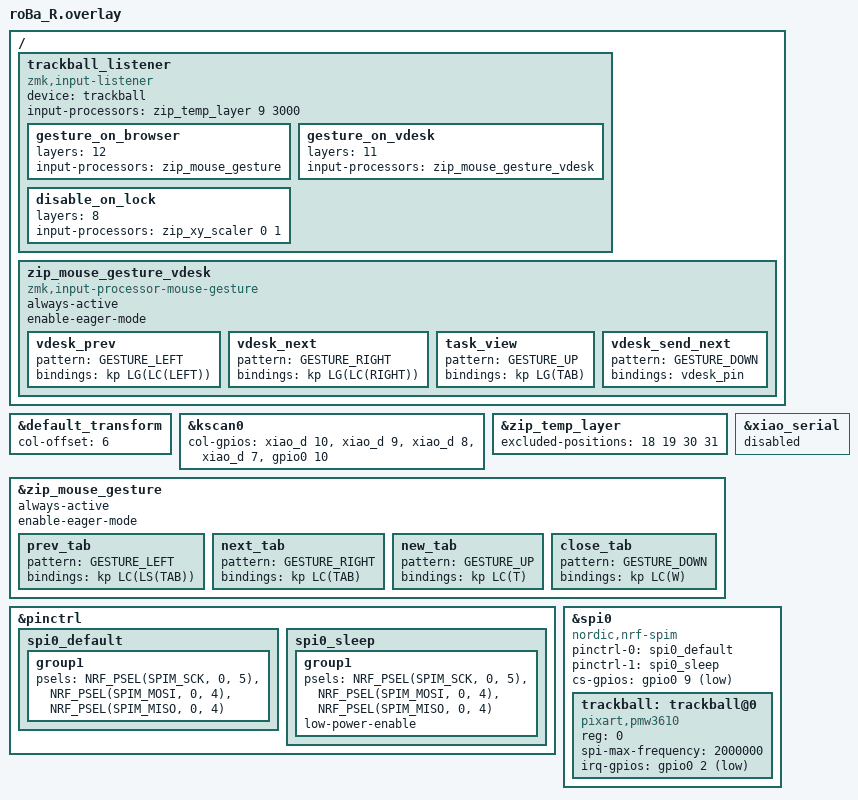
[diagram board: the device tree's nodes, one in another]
#include "roBa.dtsi"
#include <behaviors.dtsi>
#include <dt-bindings/zmk/keys.h>
#include <input/processors.dtsi>
#include <mouse-gesture.dtsi>

&default_transform {
    col-offset = <6>;
};

&kscan0 {
        col-gpios
            = <&xiao_d 10 GPIO_ACTIVE_HIGH>
            , <&xiao_d 9 GPIO_ACTIVE_HIGH>
            , <&xiao_d 8 GPIO_ACTIVE_HIGH>
            , <&xiao_d 7 GPIO_ACTIVE_HIGH>
            , <&gpio0 10 GPIO_ACTIVE_HIGH>
            ;
};

/ {
    trackball_listener {
        status = "okay";
        compatible = "zmk,input-listener";
        device = <&trackball>;
        // トラックボールが動いたらレイヤー9(MOUSE)を有効化し、3000ms動きが無ければ自動解除
        input-processors = <&zip_temp_layer 9 3000>;

        // MOUSE-BROWSER(レイヤー12)の間はトラックボールの動きを常にジェスチャーとして扱う
        gesture_on_browser {
            layers = <12>;
            input-processors = <&zip_mouse_gesture>;
        };

        // MOUSE-VERTIALDESKTOP(レイヤー11)の間はトラックボールの動きを常にジェスチャーとして扱う
        gesture_on_vdesk {
            layers = <11>;
            input-processors = <&zip_mouse_gesture_vdesk>;
        };

        // LOCK(レイヤー8、チャイルドロック中)はX/Y移動量を0倍にしてトラックボールを無効化
        disable_on_lock {
            layers = <8>;
            input-processors = <&zip_xy_scaler 0 1>;
        };
    };

    // MOUSE-BROWSERとは別パターンにするため、別インスタンスとして定義
    zip_mouse_gesture_vdesk: zip_mouse_gesture_vdesk {
        compatible = "zmk,input-processor-mouse-gesture";
        #input-processor-cells = <0>;
        always-active;
        enable-eager-mode;

        vdesk_prev {
            pattern = <GESTURE_LEFT>;
            bindings = <&kp LG(LC(LEFT))>;
        };

        vdesk_next {
            pattern = <GESTURE_RIGHT>;
            bindings = <&kp LG(LC(RIGHT))>;
        };

        task_view {
            pattern = <GESTURE_UP>;
            bindings = <&kp LG(TAB)>;
        };

        vdesk_send_next {
            pattern = <GESTURE_DOWN>;
            // Win+Tab -> Shift+F10 -> 下矢印x3 -> Enter で
            // タスクビューの右クリックメニューから「このウィンドウをすべてのデスクトップに表示する」を選ぶ
            bindings = <&vdesk_pin>;
        };
    };
};

&zip_temp_layer {
    // MOUSEレイヤーに割り当て済みのキー(J/K/M/mo10位置)は押してもレイヤーを解除しない
    excluded-positions = <18 19 30 31>;
};

&zip_mouse_gesture {
    always-active;
    enable-eager-mode;

    prev_tab {
        pattern = <GESTURE_LEFT>;
        bindings = <&kp LC(LS(TAB))>;
    };

    next_tab {
        pattern = <GESTURE_RIGHT>;
        bindings = <&kp LC(TAB)>;
    };

    new_tab {
        pattern = <GESTURE_UP>;
        bindings = <&kp LC(T)>;
    };

    close_tab {
        pattern = <GESTURE_DOWN>;
        bindings = <&kp LC(W)>;
    };
};

&pinctrl {
    spi0_default: spi0_default {
        group1 {
            psels = <NRF_PSEL(SPIM_SCK, 0, 5)>,
                <NRF_PSEL(SPIM_MOSI, 0, 4)>,
                <NRF_PSEL(SPIM_MISO, 0, 4)>;
        };
    };

    spi0_sleep: spi0_sleep {
        group1 {
            psels = <NRF_PSEL(SPIM_SCK, 0, 5)>,
                <NRF_PSEL(SPIM_MOSI, 0, 4)>,
                <NRF_PSEL(SPIM_MISO, 0, 4)>;
            low-power-enable;
        };
    };
};

&xiao_serial { status = "disabled"; };

&spi0 {
    status = "okay";
    compatible = "nordic,nrf-spim";
    pinctrl-0 = <&spi0_default>;
    pinctrl-1 = <&spi0_sleep>;
    pinctrl-names = "default", "sleep";
    cs-gpios = <&gpio0 9 GPIO_ACTIVE_LOW>;

    trackball: trackball@0 {
        status = "okay";
        compatible = "pixart,pmw3610";
        reg = <0>;
        spi-max-frequency = <2000000>;
        irq-gpios = <&gpio0 2 (GPIO_ACTIVE_LOW | GPIO_PULL_UP)>;
    };
};
